# DSS register map
Vendor: Texas Instruments
Peripheral module from a debugger description file (folder omap5430_ES2_PUBLIC).
Registers are 32-bit, read-only, no defined reset value unless marked. A register's access mark holds for its fields unless they carry their own. Offsets are as the file gives them; lines under a group give offsets from that group; [hi:lo] are bit positions; {n}, {i} and the like mark numbered series; 'fields as' and 'values as' point back to an identical list; <NAME> marks a mode.

## DSS
0x00 DSS_REVISION — This register contains the DSS revision number.
  [31:0] REVISION — IP revision
0x14 DSS_SYSSTATUS reset 0x1 — This register provides status information about the module.
  [0] RESETDONE — Internal reset monitoring
    0=rstact (Internal module reset is ongoing.); 1=rstcomp (Reset complete)
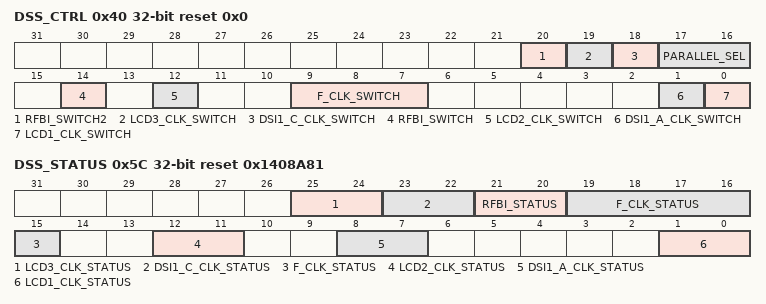
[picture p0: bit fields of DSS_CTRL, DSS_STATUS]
0x40 DSS_CTRL access per field reset 0x0 — This register contains the DSS control bits.
  [20] RFBI_SWITCH2 rw — Selects the video port 3 from DISPC or select RFBI_SWITCH bit-field If RFBI_SWITCH2 is not set, the video port selectecion is done through the bit-field RFBI_SWITCH
    0=VP1_2_Sel (The video port is selected using only RFBI_SWITCH bit-field.); 1=VP3_Sel (Video port 3 (also named third LCD output or LCD3) is selected. The bit-field RFBI_SWITCH is ignored.)
  [19] LCD3_CLK_SWITCH rw — DSS_CLK/DPLL_DSI1_C_CLK1 clock switch (multiplexer 10) Selects the clock source for the DISPC LCD3_CLK clock
    0=DSS_CLK selected (from PRCM); 1=DPLL_DSI1_C_CLK1 selected
  [18] DSI1_C_CLK_SWITCH rw — DSS_CLK/DPLL14_DSI1_C_CLK2 clock switch (multiplexer 7) Selects the clock source for the DSI1_C functional clock DSI1_C_CLK
    0=DSS_CLK selected (from PRCM); 1=DPLL_DSI1_C_CLK2 selected (from DPLL_DSI1_C)
  [17:16] PARALLEL_SEL rw — Selection between LCD1, LCD2, LCD3 and TV channel out on the parallel output (multiplexer 13)
    0=HDMI (Select HDMI channel output.); 1=LCD1 (Select LCD1 channel output.); 3=LCD3 (Select LCD3 channel output.); 2=LCD2 (Select LCD2 channel output.)
  [14] RFBI_SWITCH rw — Selects the video port from DISPC between Video port 1 and Video port 2 (multiplexer 11). If RFBI_SWITCH2 is set, RFBI_SWITCH field is ignored.
    0=VP1_Sel (Video port #1 (also named primary LCD output or LCD1) is selected (backward compatible mode)); 1=VP2_Sel (Video port #2 (also named secondary LCD output or LCD2) is selected)
  [12] LCD2_CLK_SWITCH rw — DSS_CLK clock switch (multiplexer 3) Selects the clock source for the DISPC LCD2_CLK clock
    0=DSS_CLK selected (from PRCM); 1=DPLL_DSI1_B_CLK1_Sel (Reserved)
  [9:7] F_CLK_SWITCH rw — Selects the clock source for the DISPC functional clock F_CLK
    0=DSS_CLK_selected_(from_PRCM); 1=DPLL_DSI1_A_CLK1_DPLL_DSI1_A)_1 (DPLL_DSI1_A_CLK1 selected (from DPLL_DSI1_A)); 3=DPLL_HDMI_CLK1_DPLL_HDMI)_3 (DPLL_HDMI_CLK1 selected (from DPLL_HDMI)); 4=DPLL_DSI1_C_CLK1_DPLL_DSI1_C)_4 (DPLL_DSI1_C_CLK1 selected (from DPLL_DSI1_C))
  [1] DSI1_A_CLK_SWITCH rw — DSS_CLK/DPLL_DSI1_A_CLK2 clock switch (multiplexer 4) Selects the clock source for the DSI1_A functional clock DSI1_A_CLK
    0=DSS_CLK selected (from PRCM); 1=DPLL_DSI1_A_CLK2 selected (from DSI1_A PLL)
  [0] LCD1_CLK_SWITCH rw — DSS_CLK/DPLL_DSI1_A_CLK1 clock switch (multiplexer 2) Selects the clock source for the DISPC LCD1_CLK clock
    0=DSS_CLK selected (from PRCM); 1=DPLL_DSI1_A_CLK1 selected (from DSI1_A PLL)
0x5C DSS_STATUS reset 0x1408A81 — This register contains the DSS status.
  [25:24] LCD3_CLK_STATUS — LCD3_CLK clock selection status (multiplexer 10) indicates which clock is used by the glitch-free mux selecting the source of LCD3_CLK. It is required to have the current clock and the new selected clock being running in order to be able to switch. Both clocks are used at the same time while the switch is ongoing.
    2=DPLL_DSI1_C_CLK1_Sel (DPLL_DSI1_C_CLK1 is used by DISPC as LCD3_CLK clock); 1=DSS_CLK_Sel (DSS_CLK is used as LCD3_CLK); 0=LCD3_CLK_TRANSITION (LCD3_CLK clock switch is on-going)
  [23:22] DSI1_C_CLK_STATUS — DSI1_C_CLK clock selection status (multiplexer 4) indicates which clock is used by the glitch-free mux selecting the source of DSI1_C_CLK. It is required to have the current clock and the new selected clock being running in order to be able to switch. Both clocks are used at the same time while the switch is ongoing.
    2=DPLL_DSI1_C_CLK2_Sel (DPLL_DSI1_C_CLK2 is used by DSI1_C as DSI1_C_CLK clock); 1=DSS_CLK_Sel (DSS_CLK is used by DSI1_C as DSI1_C_CLK clock); 0=DSI1_C_CLK_TRANSITION (DSI1_C_CLK clock switch is ongoing)
  [21:20] RFBI_STATUS — Video port selection status (multiplexer 11) Indicates if video port 1 or video 2 from DISPC is used to provide data to the RFBI
    2=VP3_Sel (Video port 3 (named also third LCD output or LCD3) used to provide data to RFBI); 1=VP2_Sel (Video port 2 (named also secondary LCD output or LCD2) used to provide data to RFBI); 0=VP1_Sel (Video port 1 (named also primary LCD output or LCD1) used to provide data to RFBI)
  [19:15] F_CLK_STATUS — F_CLK clock selection status (multiplexer 1) indicates which clock is used by the glitch-free mux selecting the source of F_CLK. It is required to have the current clock and the new selected clock being running in order to be able to switch. Both clocks are used at the same time while the switch is ongoing.
    2=DPLL_DSI1_A_CLK1_DISPC_F_CLK_2 (DPLL_DSI1_A_CLK1 is used by DISPC as F_CLK clock); 0=DSS_CLK_clock_switch_is_on-going; 1=DSS_CLK_is_used_by_DISPC_as_F_CLK_clock; 8=DPLL_HDMI_CLK1_DISPC_F_CLK_8 (DPLL_HDMI_CLK1 is used by DISPC as F_CLK clock); 16=DPLL_DSI1_C_CLK1_DISPC_F_CLK_16 (DPLL_DSI1_C_CLK1 is used by DISPC as F_CLK clock)
  [12:11] LCD2_CLK_STATUS — LCD2_CLK clock selection status (multiplexer 3) indicates which clock is used by the glitch-free mux selecting the source of LCD2_CLK. It is required to have the current clock and the new selected clock being running in order to be able to switch. Both clocks are used at the same time while the switch is ongoing.
    2=DPLL_DSI1_B_CLK1_Sel (Reserved); 1=DSS_CLK_Sel (DSS_CLK is used as LCD2_CLK); 0=LCD2_CLK_TRANSITION (LCD2_CLK clock switch is on-going)
  [8:7] DSI1_A_CLK_STATUS — DSI1_A_CLK clock selection status (multiplexer 4) indicates which clock is used by the glitch-free mux selecting the source of DSI1_A_CLK. It is required to have the current clock and the new selected clock being running in order to be able to switch. Both clocks are used at the same time while the switch is ongoing.
    2=DPLL_DSI_A_CLK2_Sel (DPLL_DSI1_A_CLK2 is used by DSI1_A as DSI1_A_CLK clock); 1=DSS_CLK_Sel (DSS_CLK is used by DSI1_A as DSI1_A_CLK clock); 0=DSI1_A_CLK_TRANSITION (DSI1_A_CLK clock switch is on-going)
  [1:0] LCD1_CLK_STATUS — LCD1_CLK clock selection status (multiplexer 2) indicates which clock is used by the glitch-free mux selecting the source of LCD1_CLK. It is required to have the current clock and the new selected clock being running in order to be able to switch. Both clocks are used at the same time while the switch is on going.
    2=DPLL_DSI1_A_CLK1_Sel (DPLL_DSI1_A_CLK1 is used by DISPC as LCD1_CLK clock); 1=DSS_CLK_Sel (DSS_CLK is used as LCD1_CLK); 0=LCD1_CLK_TRANSITION (LCD1_CLK clock switch is on-going)
